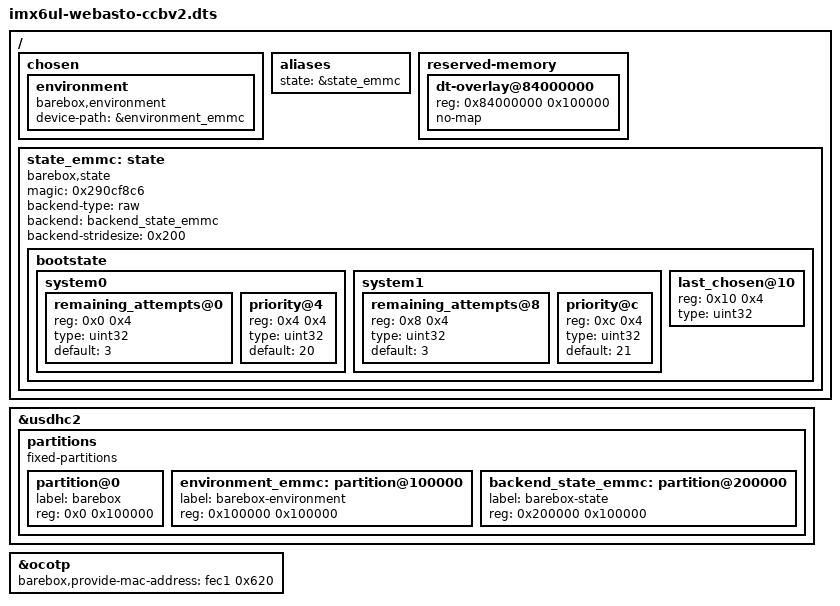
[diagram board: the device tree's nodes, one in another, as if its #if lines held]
// SPDX-License-Identifier: (GPL-2.0 OR MIT)
/*
 * Copyright (C) 2019, Webasto SE
 * Author: Johannes Eigner <johannes.eigner@webasto.com>
 */

/dts-v1/;

#include "imx6ul-webasto-ccbv2.dtsi"

/ {
	chosen {
		environment {
			compatible = "barebox,environment";
			device-path = &environment_emmc;
		};
	};

	aliases {
		state = &state_emmc;
	};

	reserved-memory {
		#address-cells = <1>;
		#size-cells = <1>;
		ranges;

		dt-overlay@84000000 {
			reg = <0x84000000 0x100000>;
			no-map;
		};
	};

	state_emmc: state {
		#address-cells = <1>;
		#size-cells = <1>;
		compatible = "barebox,state";
		magic = <0x290cf8c6>;
		backend-type = "raw";
		backend = <&backend_state_emmc>;
		backend-stridesize = <0x200>;

		bootstate {
			#address-cells = <1>;
			#size-cells = <1>;

			system0 {
				#address-cells = <1>;
				#size-cells = <1>;

				remaining_attempts@0 {
					reg = <0x0 0x4>;
					type = "uint32";
					default = <3>;
				};

				priority@4 {
					reg = <0x4 0x4>;
					type = "uint32";
					default = <20>;
				};
			};

			system1 {
				#address-cells = <1>;
				#size-cells = <1>;

				remaining_attempts@8 {
					reg = <0x8 0x4>;
					type = "uint32";
					default = <3>;
				};

				priority@c {
					reg = <0xc 0x4>;
					type = "uint32";
					default = <21>;
				};
			};

			last_chosen@10 {
				reg = <0x10 0x4>;
				type = "uint32";
			};
		};
	};
};

&usdhc2 {
	partitions {
		compatible = "fixed-partitions";
		#address-cells = <1>;
		#size-cells = <1>;

		partition@0 {
			label = "barebox";
			reg = <0x0 0x100000>;
		};

		environment_emmc: partition@100000 {
			label = "barebox-environment";
			reg = <0x100000 0x100000>;
		};

		backend_state_emmc: partition@200000 {
			label = "barebox-state";
			reg = <0x200000 0x100000>;
		};
	};
};


&ocotp {
	barebox,provide-mac-address = <&fec1 0x620>;
};

/* include the FIT public key for verifying on demand */
#ifdef CONFIG_BOOTM_FITIMAGE_PUBKEY
#include CONFIG_BOOTM_FITIMAGE_PUBKEY
#endif
